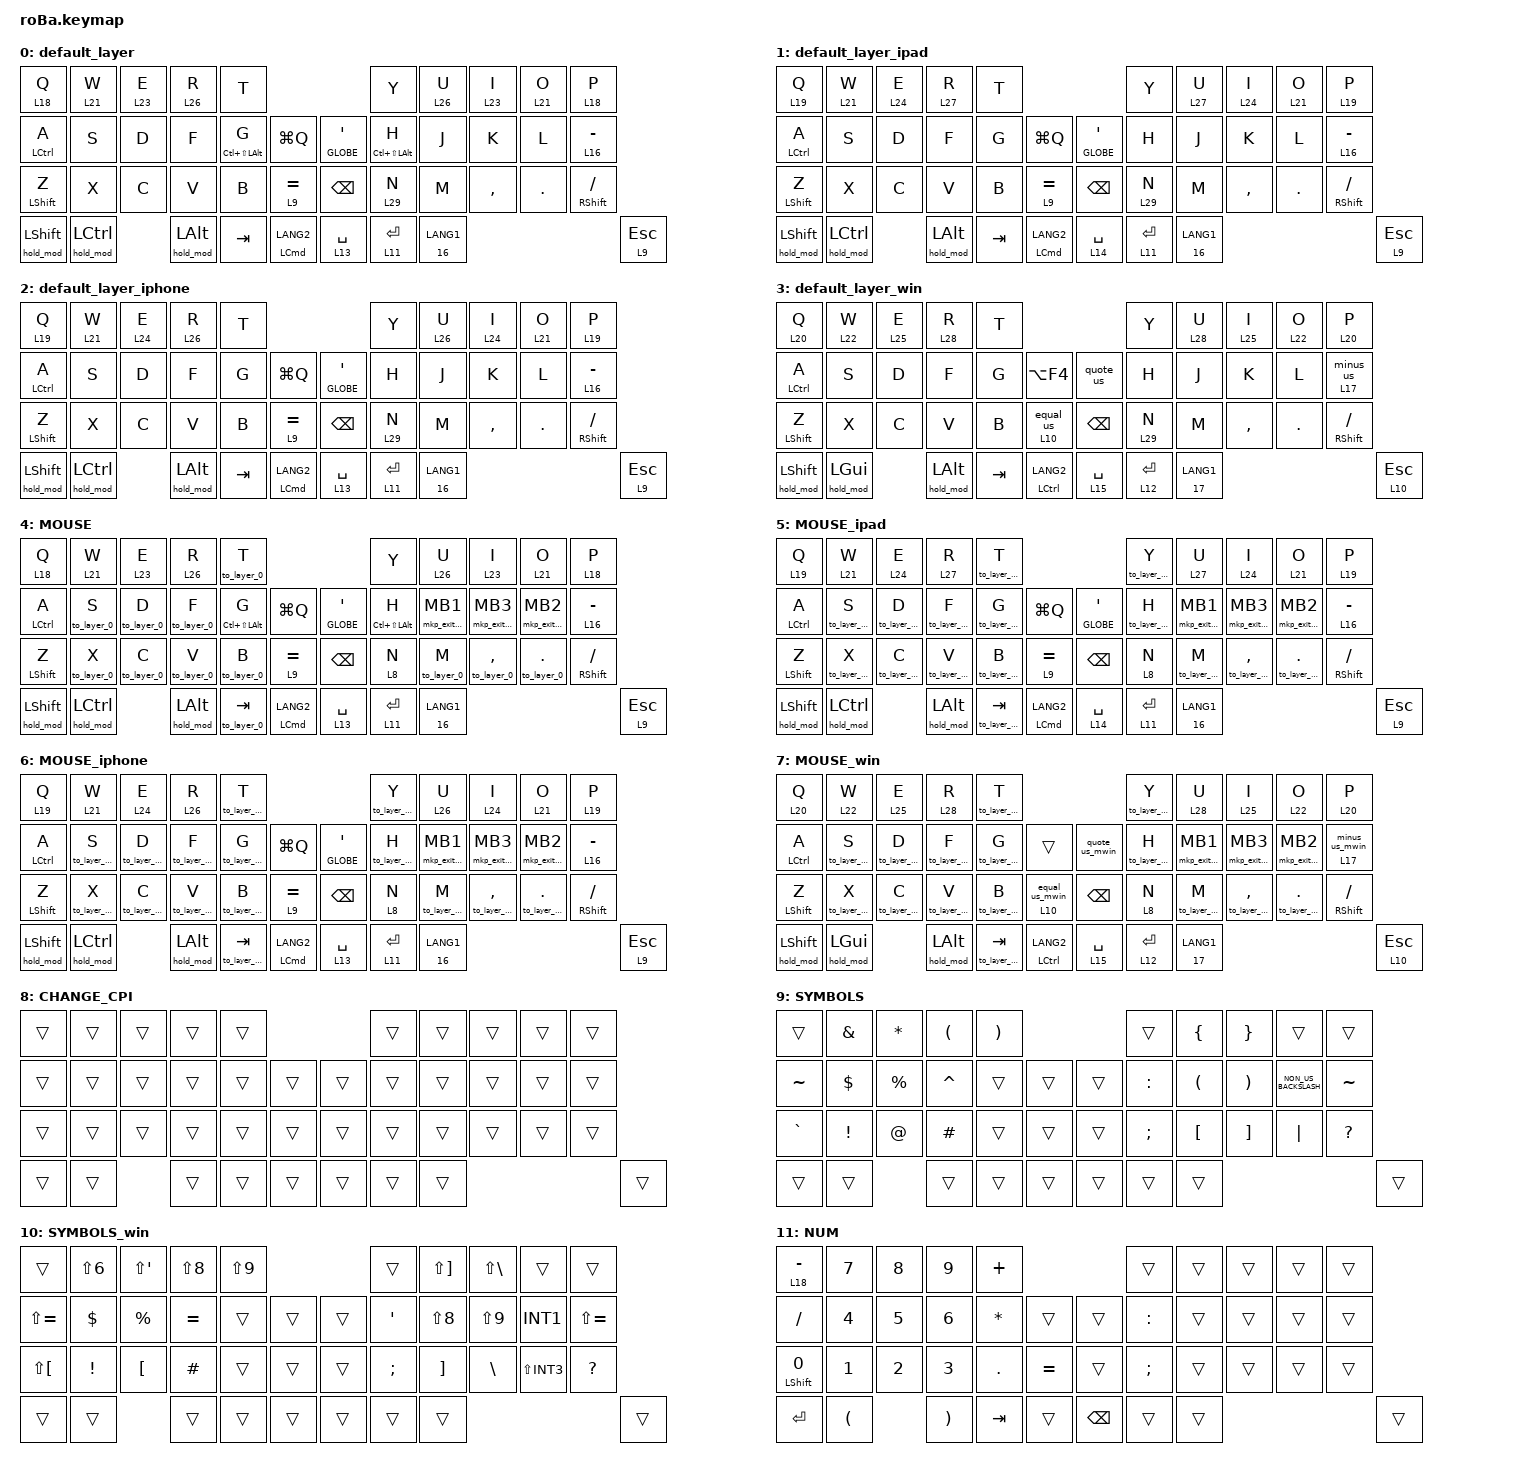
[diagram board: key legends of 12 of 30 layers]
// スクロール量。&msc SCRL_UP/DOWN が SCRL_UP マクロ経由で参照するため、
// pointing.h とエンコーダbehavior(roBa_encoder_behaviors.dtsi)のincludeより
// 必ず前で定義する（後ろに置くと既定値(10)に戻りスクロールが事実上無効になる）。

#define ZMK_POINTING_DEFAULT_SCRL_VAL 80

#include <dt-bindings/zmk/modifiers.h>
#include <behaviors.dtsi>
#include <dt-bindings/zmk/bt.h>
#include <dt-bindings/zmk/keys.h>
#include <dt-bindings/zmk/pointing.h>
#include "roBa_encoder_behaviors.dtsi"

&mt {
    flavor = "balanced";
    quick-tap-ms = <0>;
};

&trackball {
    // 自動マウス層はOS別に出し分けるため、ドライバ側は無効化(-1)。
    // roBa_R.overlay の zip_temp_layer で Mac=層4 / Windows=層7 を切替える。

    automouse-layer = <(-1)>;

    // 18=Mac SCROLL, 20=SCROLL_win（Windows用）。Windowsでもスクロールを有効化。
    // ※editorでレイヤーを増減すると番号がズレるので、SCROLL_winの位置を要確認。

    scroll-layers = <18 19 20>;

    // iPad(層1)等のCPIは overlay の zip_xy_scaler で調整（旧実装は低速CPI=snipe機能だった）。
    // snipe-layers = <1 4>;  // 廃止: iPadをzip_xy_scaler化(overlay)したため。
    // 精密モード(層28)が最上位になるとsnipe判定が外れる問題を回避。CPIは全OS zip_xy_scalerに統一。

    browsing_arrows {
        layers = <21>;
        bindings =
            <&kp LC(TAB)>,
            // 右: 次のタブ,,,,,,,,,,,,,,,,,,,,,,,,,,,,,,,,,,,,,,,,,,,,,,,,,,,,,,,,,,,,,,,,,,,,,,,,,,,,,,,,,,,
            <&kp LC(LS(TAB))>,
            // 左: 前のタブ,,,,,,,,,,,,,,,,,,,,,,,,,,,,,,,,,,,,,,,,,,,,,,,,,,,,,,,,,,,,,,,,,,,,,,,,,,,,,,,,,,,
            <&kp LG(T)>,
            // 上: 新規タブ,,,,,,,,,,,,,,,,,,,,,,,,,,,,,,,,,,,,,,,,,,,,,,,,,,,,,,,,,,,,,,,,,,,,,,,,,,,,,,,,,,,
            <&kp LG(W)>;

        // 下: タブを閉じる

        tick = <150>;
        wait-ms = <5>;
        tap-ms = <5>;
    };

    desktop_arrows {
        layers = <23>;
        bindings =
            <&kp LC(LEFT)>,
            // 右(逆): デスクトップ左,,,,,,,,,,,,,,,,,,,,,,,,,,,,,,,,,,,,,,,,,,,,,,,,,,,,,,,,,,,,,,,,,,,,,,,,,,,,,,,,,,,
            <&kp LC(RIGHT)>,
            // 左(逆): デスクトップ右,,,,,,,,,,,,,,,,,,,,,,,,,,,,,,,,,,,,,,,,,,,,,,,,,,,,,,,,,,,,,,,,,,,,,,,,,,,,,,,,,,,
            <&kp LC(UP)>,
            // 上: Mission Control,,,,,,,,,,,,,,,,,,,,,,,,,,,,,,,,,,,,,,,,,,,,,,,,,,,,,,,,,,,,,,,,,,,,,,,,,,,,,,,,,,,
            <&kp LS(LA(D))>;

        // 下: Shift+Opt+D

        tick = <150>;
        wait-ms = <5>;
        tap-ms = <5>;
    };

    window_arrows {
        layers = <26>;
        bindings =
            <&kp LC(LA(RIGHT))>,
            // 右: 右半分,,,,,,,,,,,,,,,,,,,,,,,,,,,,,,,,,,,,,,,,,,,,,,,,,,,,,,,,,,,,,,,,,,,,,,,,,,,,,,,,,,,
            <&kp LC(LA(LEFT))>,
            // 左: 左半分,,,,,,,,,,,,,,,,,,,,,,,,,,,,,,,,,,,,,,,,,,,,,,,,,,,,,,,,,,,,,,,,,,,,,,,,,,,,,,,,,,,
            <&kp LC(LA(ENTER))>,
            // 上: 最大化,,,,,,,,,,,,,,,,,,,,,,,,,,,,,,,,,,,,,,,,,,,,,,,,,,,,,,,,,,,,,,,,,,,,,,,,,,,,,,,,,,,
            <&kp LS(LG(T))>;

        // 下: Shift+Cmd+T

        tick = <150>;
        wait-ms = <5>;
        tap-ms = <5>;
    };

    // ===== Windows用ジェスチャー（層22/25/28）=====
    // Mac版(21/23/26)と別ブロックにして、Windows相当のショートカットを割当てる。

    browsing_arrows_win {
        layers = <22>;
        bindings =
            <&kp LC(TAB)>,
            // 右: 次のタブ,,,,,,,,,,,,,,,,,,,,,,,,,,,,,,,,,,,,,,,,,,,,,,,,,,,,,,,,,,,,,,,,,,,,,,,,
            <&kp LC(LS(TAB))>,
            // 左: 前のタブ,,,,,,,,,,,,,,,,,,,,,,,,,,,,,,,,,,,,,,,,,,,,,,,,,,,,,,,,,,,,,,,,,,,,,,,,
            <&kp LC(T)>,
            // 上: 新規タブ,,,,,,,,,,,,,,,,,,,,,,,,,,,,,,,,,,,,,,,,,,,,,,,,,,,,,,,,,,,,,,,,,,,,,,,,
            <&kp LC(W)>;

        // 下: タブを閉じる

        tick = <150>;
        wait-ms = <5>;
        tap-ms = <5>;
    };

    desktop_arrows_win {
        layers = <25>;
        bindings =
            <&kp LG(LC(LEFT))>,
            // 右(逆): 仮想デスクトップ左,,,,,,,,,,,,,,,,,,,,,,,,,,,,,,,,,,,,,,,,,,,,,,,,,,,,,,,,,,,,,,,,,,,,,,,,
            <&kp LG(LC(RIGHT))>,
            // 左(逆): 仮想デスクトップ右,,,,,,,,,,,,,,,,,,,,,,,,,,,,,,,,,,,,,,,,,,,,,,,,,,,,,,,,,,,,,,,,,,,,,,,,
            <&kp LG(TAB)>,
            // 上: タスクビュー,,,,,,,,,,,,,,,,,,,,,,,,,,,,,,,,,,,,,,,,,,,,,,,,,,,,,,,,,,,,,,,,,,,,,,,,
            <&dup_tab_win>;

        // 下: タブを複製（Alt+D → Alt+Enter）

        tick = <150>;
        wait-ms = <5>;
        tap-ms = <5>;
    };

    window_arrows_win {
        layers = <28>;
        bindings =
            <&kp LG(RIGHT)>,
            // 右: 右半分スナップ,,,,,,,,,,,,,,,,,,,,,,,,,,,,,,,,,,,,,,,,,,,,,,,,,,,,,,,,,,,,,,,,,,,,,,,,
            <&kp LG(LEFT)>,
            // 左: 左半分スナップ,,,,,,,,,,,,,,,,,,,,,,,,,,,,,,,,,,,,,,,,,,,,,,,,,,,,,,,,,,,,,,,,,,,,,,,,
            <&kp LG(UP)>,
            // 上: 最大化,,,,,,,,,,,,,,,,,,,,,,,,,,,,,,,,,,,,,,,,,,,,,,,,,,,,,,,,,,,,,,,,,,,,,,,,
            <&kp LC(LS(T))>;

        // 下: 閉じたタブ復活

        tick = <150>;
        wait-ms = <5>;
        tap-ms = <5>;
    };

    // ===== iPad用ジェスチャー（層24 = Desktop_Jesture_ipad）=====

    desktop_arrows_ipad {
        layers = <24>;
        bindings =
            <&split_left>,
            // 右: 🌐+←（Split View 左）,,,,,,,,,,,,,,,,,,,,,,,,,,,,,,,,,,,,,,,,,,,,,,,,,,,,,,,,,,,,,,,,
            <&split_right>,
            // 左: 🌐+→（Split View 右）,,,,,,,,,,,,,,,,,,,,,,,,,,,,,,,,,,,,,,,,,,,,,,,,,,,,,,,,,,,,,,,,
            <&app_switcher>,
            // 上: 🌐+↑（Appスイッチャー）,,,,,,,,,,,,,,,,,,,,,,,,,,,,,,,,,,,,,,,,,,,,,,,,,,,,,,,,,,,,,,,,
            <&ipad_home>;

        // 下: 🌐+H（ホーム）

        tick = <150>;
        wait-ms = <5>;
        tap-ms = <5>;
    };

    // ===== iPad用ウィンドウジェスチャー（層27 = Window_Jesture_ipad）=====
    // 設定はMac版(window_arrows)と同一。

    window_arrows_ipad {
        layers = <27>;
        bindings =
            <&ipad_tile_right>,
            // 右: 右にタイル（🌐+Ctrl+→）,,,,,,,,,,,,,,,,,,,
            <&ipad_tile_left>,
            // 左: 左にタイル（🌐+Ctrl+←）,,,,,,,,,,,,,,,,,,,
            <&ipad_fullscreen>,
            // 上: フルスクリーン（🌐+F）,,,,,,,,,,,,,,,,,,,
            <&ipad_show_windows>;

        // 下: 全ウィンドウ表示（🌐+↓）

        tick = <150>;
        wait-ms = <5>;
        tap-ms = <5>;
    };

    // ===== FUNCTION(層16)ジェスチャー: 左右振りでウィンドウを外部ディスプレイへ移動 =====
    // FUNCTIONは右LANGホールド中でCmd(RGUI)が保持されるため、&nomodで保持Cmdを外してから
    // 完全なショートカットを送る。Mac: Rectangle「次/前のディスプレイへ移動」=Ctrl+Opt+Cmd+→/←。

    function_display_move {
        layers = <16>;
        bindings =
            <&nomod LC(LA(LG(RIGHT)))>,
            // 右: 次(右)のディスプレイへ移動,,,,,,,,,,,,,
            <&nomod LC(LA(LG(LEFT)))>,
            // 左: 前(左)のディスプレイへ移動,,,,,,,,,,,,,
            <&nomod LC(LA(ENTER))>,
            // 上: 全画面表示（Magnet 最大化 = Ctrl+Opt+Enter）,,,,,,,,,,,,,
            <&nomod LC(LA(LG(C)))>;

        // 下: 画面中央へ移動（Ctrl+Opt+Cmd+C、サイズは維持）

        tick = <150>;
        wait-ms = <5>;
        tap-ms = <5>;
    };

    // Windows版(層17 FUNCTION_win): 「次/前のモニターへ移動」=Win+Shift+→/←。
    // FUNCTION_winはCtrl(RCTRL)保持なので&nomodで外す。

    function_display_move_win {
        layers = <17>;
        bindings =
            <&nomod LG(LS(RIGHT))>,
            // 右: 次(右)のモニターへ移動,,,,,,,,,,,,,
            <&nomod LG(LS(LEFT))>,
            // 左: 前(左)のモニターへ移動,,,,,,,,,,,,,
            <&nomod LG(UP)>,
            // 上: 全画面表示（Win+↑ 最大化）,,,,,,,,,,,,,
            <&none>;

        // 下: なし

        tick = <150>;
        wait-ms = <5>;
        tap-ms = <5>;
    };
};

/ {
    combos {
        compatible = "zmk,combos";

        num_toggle {
            bindings = <&tog 11>;
            key-positions = <1 0>;
            layers = <0 1 2 4 5 6 11>;
        };

        num_toggle_win {
            bindings = <&tog 12>;
            key-positions = <0 1>;
            layers = <3 7 12>;
        };

        // U+I 同時押しで、現在のOSに応じたスクロール層をトグル。
        // スコープに「デフォルト層＋マウス層＋トグル先(OFF用)」を含める。

        scroll_toggle_mac {
            bindings = <&tog 18>;
            key-positions = <8 9>;
            layers = <0 4 18>;
        };

        scroll_toggle_ipad {
            bindings = <&tog 19>;
            key-positions = <8 9>;
            layers = <1 2 5 6 19>;
        };

        scroll_toggle_win {
            bindings = <&tog 20>;
            key-positions = <8 9>;
            layers = <3 7 20>;
        };

        capslock {
            bindings = <&kp CAPSLOCK>;
            key-positions = <37 38>;
        };

        // Escapeはlayers指定なしだと全OSで発火し、&to_layer_0がBTに触れず
        // レイヤー0(Mac)へ直接切替するため、Windows/iPad/iPhone使用中に発火すると
        // Macレイヤーへ乗っ取られる（Ctrl位置がCmd化しWinキー誤送出・エンコーダ方向反転）。
        // OS別に分離し、最上位アクティブレイヤー基準（combo.cで確認済み）でスコープする。
        // 注意: 精密モード(層8)中はどのOS版も発火しない（scroll_toggle系と同じ制約）。
        // alfred: 実行時にOSデフォルトレイヤー(0-3)を判定するalfred_smart behaviorに統合
        // (2026-07-13)。全デフォルト層/マウス層/精密モード層のどこからでも正しいOSへ発火する。

        alfred {
            bindings = <&alfred_smart>;
            key-positions = <41 39>;
            layers = <0 1 2 3 4 5 6 7 8>;
            require-prior-idle-ms = <200>;
        };

        Escape {
            bindings = <&to_layer_0 ESC>;
            key-positions = <0 39>;
            layers = <0 4>;
            require-prior-idle-ms = <200>;
        };

        Escape_win {
            bindings = <&to_layer_0_win ESC>;
            key-positions = <0 39>;
            layers = <3 7>;
            require-prior-idle-ms = <200>;
        };

        Escape_ipad {
            bindings = <&to_layer_0_ipad ESC>;
            key-positions = <0 39>;
            layers = <1 5>;
            require-prior-idle-ms = <200>;
        };

        Escape_iphone {
            bindings = <&to_layer_0_iphone ESC>;
            key-positions = <0 39>;
            layers = <2 6>;
            require-prior-idle-ms = <200>;
        };

        // BluetoothコンボはNキー(位置29)+Y/U/I/O/Pの組み合わせで、"know"/"funny"/
        // "into"/"menu"/"input"等の日常語で頻出する2文字と一致するため、layers指定
        // なし(常時発火)と合わさってタイピング中に誤爆しやすい。require-prior-idle-ms
        // で「直前の通常キー入力から200ms以内はコンボ扱いしない」を追加し、連続タイピング
        // 中は個々のキーとして送出、意図的に一拍置いて押した時だけコンボとして発火させる。

        Bluetooth_1 {
            bindings = <&bt_mac>;
            key-positions = <5 29>;
            require-prior-idle-ms = <200>;
        };

        Bluetooth_2 {
            bindings = <&bt_ipad>;
            key-positions = <6 29>;
            require-prior-idle-ms = <200>;
        };

        Bluetooth_3 {
            bindings = <&bt_ipad_mini>;
            key-positions = <7 29>;
            require-prior-idle-ms = <200>;
        };

        Bluetooth_4 {
            bindings = <&bt_iphone>;
            key-positions = <8 29>;
            require-prior-idle-ms = <200>;
        };

        Bluetooth_5 {
            bindings = <&bt_win>;
            key-positions = <9 29>;
            require-prior-idle-ms = <200>;
        };

        right_arrow {
            bindings = <&right_arrow>;
            key-positions = <41 20>;
        };

        left_arrow {
            bindings = <&left_arrow>;
            key-positions = <41 18>;
        };

        down_arrow {
            bindings = <&down_arrow>;
            key-positions = <41 19>;
        };

        up_arrow {
            bindings = <&up_arrow>;
            key-positions = <41 7>;
        };

        // m + , (位置30/31) で精密モード(層28 CHANGE_CPI)をトグル。
        // スコープ=各OSのデフォルト層＋マウス層＋28(OFF用)。

        change_cpi_toggle {
            bindings = <&tog 8>;
            key-positions = <30 31>;
            layers = <0 1 2 4 5 6 3 7 8>;
        };

        mouse_left_click {
            bindings = <&mkp MB1>;
            key-positions = <18 19>;
        };

        mouse_right_click {
            bindings = <&mkp MB2>;
            key-positions = <19 20>;
        };

        mouse_middle-click {
            bindings = <&mkp MB3>;
            key-positions = <18 20>;
        };

        // Z + X 同時押しで LSHFT の押しっぱなし状態をトグル。エンコーダのmod-morph
        // （encoder_msc_mac_shift_hscroll等）がShift押下中かを見て上下を反転させる
        // 仕組みを利用し、物理的にShiftを押さえ続けなくても横スクロール相当に切替
        // できる。全レイヤー共通（layers指定なし）。もう一度押すと解除。
    };

    macros {
        left_arrow: left_arrow {
            compatible = "zmk,behavior-macro";
            #binding-cells = <0>;
            wait-ms = <40>;
            tap-ms = <30>;
            bindings = <&kp RGUI &kp Z &kp H>;
            label = "LEFT_ARROW";
        };

        down_arrow: down_arrow {
            compatible = "zmk,behavior-macro";
            #binding-cells = <0>;
            wait-ms = <40>;
            tap-ms = <30>;
            bindings = <&kp RGUI &kp Z &kp J>;
            label = "DOWN_ARROW";
        };

        up_arrow: up_arrow {
            compatible = "zmk,behavior-macro";
            #binding-cells = <0>;
            wait-ms = <40>;
            tap-ms = <30>;
            bindings = <&kp RGUI &kp Z &kp K>;
            label = "UP_ARROW";
        };

        right_arrow: right_arrow {
            compatible = "zmk,behavior-macro";
            #binding-cells = <0>;
            wait-ms = <40>;
            tap-ms = <30>;
            bindings = <&kp RGUI &kp Z &kp L>;
            label = "RIGHT_ARROW";
        };

        to_layer_0: to_layer_0 {
            compatible = "zmk,behavior-macro-one-param";
            #binding-cells = <1>;
            bindings = <&to_base_keep_cpi 0 &macro_param_1to1 &kp MACRO_PLACEHOLDER>;
            label = "TO_LAYER_0";
        };

        to_layer_0_win: to_layer_0_win {
            compatible = "zmk,behavior-macro-one-param";
            #binding-cells = <1>;
            bindings = <&to_base_keep_cpi 3 &macro_param_1to1 &kp MACRO_PLACEHOLDER>;
            label = "TO_LAYER_0_WIN";
        };

        to_layer_0_ipad: to_layer_0_ipad {
            compatible = "zmk,behavior-macro-one-param";
            #binding-cells = <1>;
            bindings = <&to_base_keep_cpi 1 &macro_param_1to1 &kp MACRO_PLACEHOLDER>;
            label = "TO_LAYER_0_IPAD";
        };

        to_layer_0_iphone: to_layer_0_iphone {
            compatible = "zmk,behavior-macro-one-param";
            #binding-cells = <1>;
            bindings = <&to_base_keep_cpi 2 &macro_param_1to1 &kp MACRO_PLACEHOLDER>;
            label = "TO_LAYER_0_IPHONE";
        };

        // Windows: タブを複製。Alt+D でアドレスバーのURLを選択し、
        // Alt+Enter で同じURLを新規タブで開く（＝複製）。

        dup_tab_win: dup_tab_win {
            compatible = "zmk,behavior-macro";
            #binding-cells = <0>;
            wait-ms = <30>;
            tap-ms = <30>;
            bindings = <&kp LA(D) &kp LA(ENTER)>;
            label = "DUP_TAB_WIN";
        };

        // iPad用 Globe(🌐)ショートカット。GLOBE保持→キーをタップ→GLOBE解放。
        // GLOBEはコンシューマ入力切替コードなので &kp GLOBE(x) は不可、マクロ必須。

        control_center: control_center {
            compatible = "zmk,behavior-macro";
            #binding-cells = <0>;
            wait-ms = <10>;
            tap-ms = <10>;
            bindings =
                <&macro_press>,
                <&kp GLOBE>,
                <&macro_tap>,
                <&kp C>,
                <&macro_release>,
                <&kp GLOBE>;

            label = "CONTROL_CENTER";
        };

        app_switcher: app_switcher {
            compatible = "zmk,behavior-macro";
            #binding-cells = <0>;
            wait-ms = <10>;
            tap-ms = <10>;
            bindings =
                <&macro_press>,
                <&kp GLOBE>,
                <&macro_tap>,
                <&kp UP_ARROW>,
                <&macro_release>,
                <&kp GLOBE>;

            label = "APP_SWITCHER";
        };

        notif_center: notif_center {
            compatible = "zmk,behavior-macro";
            #binding-cells = <0>;
            wait-ms = <10>;
            tap-ms = <10>;
            bindings =
                <&macro_press>,
                <&kp GLOBE>,
                <&macro_tap>,
                <&kp N>,
                <&macro_release>,
                <&kp GLOBE>;

            label = "NOTIF_CENTER";
        };

        split_left: split_left {
            compatible = "zmk,behavior-macro";
            #binding-cells = <0>;
            wait-ms = <10>;
            tap-ms = <10>;
            bindings =
                <&macro_press>,
                <&kp GLOBE>,
                <&macro_tap>,
                <&kp LEFT_ARROW>,
                <&macro_release>,
                <&kp GLOBE>;

            label = "SPLIT_LEFT";
        };

        split_right: split_right {
            compatible = "zmk,behavior-macro";
            #binding-cells = <0>;
            wait-ms = <10>;
            tap-ms = <10>;
            bindings =
                <&macro_press>,
                <&kp GLOBE>,
                <&macro_tap>,
                <&kp RIGHT_ARROW>,
                <&macro_release>,
                <&kp GLOBE>;

            label = "SPLIT_RIGHT";
        };

        ipad_home: ipad_home {
            compatible = "zmk,behavior-macro";
            #binding-cells = <0>;
            wait-ms = <10>;
            tap-ms = <10>;
            bindings =
                <&macro_press>,
                <&kp GLOBE>,
                <&macro_tap>,
                <&kp H>,
                <&macro_release>,
                <&kp GLOBE>;

            label = "IPAD_HOME";
        };

        // iPadOS ウィンドウ操作（Globe併用）。Macのウィンドウ分割の代替。

        ipad_tile_left: ipad_tile_left {
            compatible = "zmk,behavior-macro";
            #binding-cells = <0>;
            wait-ms = <10>;
            tap-ms = <10>;
            bindings =
                <&macro_press>,
                <&kp GLOBE>,
                <&macro_tap>,
                <&kp LC(LEFT_ARROW)>,
                <&macro_release>,
                <&kp GLOBE>;

            label = "IPAD_TILE_LEFT";
        };

        ipad_tile_right: ipad_tile_right {
            compatible = "zmk,behavior-macro";
            #binding-cells = <0>;
            wait-ms = <10>;
            tap-ms = <10>;
            bindings =
                <&macro_press>,
                <&kp GLOBE>,
                <&macro_tap>,
                <&kp LC(RIGHT_ARROW)>,
                <&macro_release>,
                <&kp GLOBE>;

            label = "IPAD_TILE_RIGHT";
        };

        ipad_fullscreen: ipad_fullscreen {
            compatible = "zmk,behavior-macro";
            #binding-cells = <0>;
            wait-ms = <10>;
            tap-ms = <10>;
            bindings =
                <&macro_press>,
                <&kp GLOBE>,
                <&macro_tap>,
                <&kp F>,
                <&macro_release>,
                <&kp GLOBE>;

            label = "IPAD_FULLSCREEN";
        };

        ipad_show_windows: ipad_show_windows {
            compatible = "zmk,behavior-macro";
            #binding-cells = <0>;
            wait-ms = <10>;
            tap-ms = <10>;
            bindings =
                <&macro_press>,
                <&kp GLOBE>,
                <&macro_tap>,
                <&kp DOWN_ARROW>,
                <&macro_release>,
                <&kp GLOBE>;

            label = "IPAD_SHOW_WINDOWS";
        };

        // FUNCTION層は右LANGホールドでCmd/Ctrlを保持中。マウスボタンに修飾が
        // 乗ると「戻る/進む」が新タブで開く等の誤動作になるため、保持中modを
        // 一時解除→ボタン送出→復帰する（&mkpを包む）。nomodのマウスボタン版。

        mb_back_mac: mb_back_mac {
            compatible = "zmk,behavior-macro";
            #binding-cells = <0>;
            bindings =
                <&macro_release>,
                <&kp RGUI>,
                <&macro_tap>,
                <&mkp MB4>,
                <&macro_press>,
                <&kp RGUI>;

            label = "MB_BACK_MAC";
        };

        mb_fwd_mac: mb_fwd_mac {
            compatible = "zmk,behavior-macro";
            #binding-cells = <0>;
            bindings =
                <&macro_release>,
                <&kp RGUI>,
                <&macro_tap>,
                <&mkp MB5>,
                <&macro_press>,
                <&kp RGUI>;

            label = "MB_FWD_MAC";
        };

        mb_back_win: mb_back_win {
            compatible = "zmk,behavior-macro";
            #binding-cells = <0>;
            bindings =
                <&macro_release>,
                <&kp RCTRL>,
                <&macro_tap>,
                <&mkp MB4>,
                <&macro_press>,
                <&kp RCTRL>;

            label = "MB_BACK_WIN";
        };

        mb_fwd_win: mb_fwd_win {
            compatible = "zmk,behavior-macro";
            #binding-cells = <0>;
            bindings =
                <&macro_release>,
                <&kp RCTRL>,
                <&macro_tap>,
                <&mkp MB5>,
                <&macro_press>,
                <&kp RCTRL>;

            label = "MB_FWD_WIN";
        };

        // Bluetoothプロファイル切替＋デフォルトレイヤー切替を同時に行う。
        // 2026-07: iPad Pro購入に伴い再編成。
        // prof0=Mac(層0) / prof1=iPad Pro(層1) / prof2=iPad mini(層1) / prof3=iPhone(層2) / prof4=Windows(層3)。
        // iPad Pro/iPad miniは共にiPadOS用の挙動(層1)を共有し、物理的なBluetoothプロファイル番号だけが異なる。

        bt_mac: bt_mac {
            compatible = "zmk,behavior-macro";
            #binding-cells = <0>;
            bindings = <&bt BT_SEL 0 &to 0>;
            label = "BT_MAC";
        };

        bt_ipad: bt_ipad {
            compatible = "zmk,behavior-macro";
            #binding-cells = <0>;
            bindings = <&bt BT_SEL 1 &to 1>;
            label = "BT_IPAD_PRO";
        };

        bt_ipad_mini: bt_ipad_mini {
            compatible = "zmk,behavior-macro";
            #binding-cells = <0>;
            bindings = <&bt BT_SEL 2 &to 1>;
            label = "BT_IPAD_MINI";
        };

        bt_iphone: bt_iphone {
            compatible = "zmk,behavior-macro";
            #binding-cells = <0>;
            bindings = <&bt BT_SEL 3 &to 2>;
            label = "BT_IPHONE";
        };

        bt_win: bt_win {
            compatible = "zmk,behavior-macro";
            #binding-cells = <0>;
            bindings = <&bt BT_SEL 4 &to 3>;
            label = "BT_WIN";
        };

        mkp_exit_AML: mkp_exit_AML {
            compatible = "zmk,behavior-macro-one-param";
            #binding-cells = <1>;
            bindings =
                <&macro_press>,
                <&macro_param_1to1 &mkp MACRO_PLACEHOLDER>,
                <&macro_pause_for_release>,
                <&macro_release>,
                <&macro_param_1to1 &mkp MACRO_PLACEHOLDER>,
                <&macro_tap>,
                <&sl 4>;

            label = "MKP_EXIT_AML";
        };

        mkp_exit_AML_win: mkp_exit_AML_win {
            compatible = "zmk,behavior-macro-one-param";
            #binding-cells = <1>;
            bindings =
                <&macro_press>,
                <&macro_param_1to1 &mkp MACRO_PLACEHOLDER>,
                <&macro_pause_for_release>,
                <&macro_release>,
                <&macro_param_1to1 &mkp MACRO_PLACEHOLDER>,
                <&macro_tap>,
                <&sl 7>;

            label = "MKP_EXIT_AML_WIN";
        };

        mkp_exit_AML_ipad: mkp_exit_AML_ipad {
            compatible = "zmk,behavior-macro-one-param";
            #binding-cells = <1>;
            bindings =
                <&macro_press>,
                <&macro_param_1to1 &mkp MACRO_PLACEHOLDER>,
                <&macro_pause_for_release>,
                <&macro_release>,
                <&macro_param_1to1 &mkp MACRO_PLACEHOLDER>,
                <&macro_tap>,
                <&sl 5>;

            label = "MKP_EXIT_AML_IPAD";
        };

        mkp_exit_AML_iphone: mkp_exit_AML_iphone {
            compatible = "zmk,behavior-macro-one-param";
            #binding-cells = <1>;
            bindings =
                <&macro_press>,
                <&macro_param_1to1 &mkp MACRO_PLACEHOLDER>,
                <&macro_pause_for_release>,
                <&macro_release>,
                <&macro_param_1to1 &mkp MACRO_PLACEHOLDER>,
                <&macro_tap>,
                <&sl 6>;

            label = "MKP_EXIT_AML_IPHONE";
        };
    };

    behaviors {
        cmd_mo: cmd_mo {
            compatible = "zmk,behavior-cmd-mo";
            #binding-cells = <1>;
        };

        nomod: nomod {
            compatible = "zmk,behavior-nomod";
            #binding-cells = <1>;
        };

        ctrl_mo: ctrl_mo {
            compatible = "zmk,behavior-ctrl-mo";
            #binding-cells = <1>;
        };

        to_base_keep_cpi: to_base_keep_cpi {
            compatible = "zmk,behavior-to-base-keep-cpi";
            #binding-cells = <1>;
        };

        toggle_lshift: toggle_lshift {
            compatible = "zmk,behavior-toggle-lshift";
            #binding-cells = <0>;
        };

        rlang: rlang {
            compatible = "zmk,behavior-hold-tap";
            #binding-cells = <2>;
            flavor = "balanced";
            tapping-term-ms = <150>;
            hold-while-undecided;
            bindings = <&cmd_mo>, <&kp>;
        };

        rlang_win: rlang_win {
            compatible = "zmk,behavior-hold-tap";
            #binding-cells = <2>;
            flavor = "balanced";
            tapping-term-ms = <150>;
            hold-while-undecided;
            bindings = <&ctrl_mo>, <&kp>;
        };

        // 左親指Cmd/Ctrl(LANG2)専用: 押下瞬間から修飾キーを有効化(Karabiner to_if_alone相当)
        // &mt本体はホームロー全体に影響するため専用ノードを新設
        // 修飾キー保持専用。&kp と違いHIDへ直接登録し、離すときは参照カウントを
        // 0まで排出する（Cmd固着＝再起動でしか直らない不具合の対策・2026-07-31）。

        hold_mod: hold_mod {
            compatible = "zmk,behavior-hold-mod";
            #binding-cells = <1>;
        };

        mt_fast: mt_fast {
            compatible = "zmk,behavior-hold-tap";
            #binding-cells = <2>;
            flavor = "hold-preferred";
            tapping-term-ms = <150>;
            hold-while-undecided;
            bindings = <&hold_mod>, <&kp>;
        };

        alfred_smart: alfred_smart {
            compatible = "zmk,behavior-alfred-smart";
            #binding-cells = <0>;
        };

        // MOUSE_win(層17)用 US記号補正: タップで層16へexitしつつUS記号を出す

        quote_us_mwin: quote_us_mwin {
            compatible = "zmk,behavior-mod-morph";
            #binding-cells = <0>;
            bindings = <&to_layer_0_win LS(N7)>, <&to_layer_0_win LS(N2)>;

            mods = <(MOD_LSFT|MOD_RSFT)>;
        };

        minus_us_mwin: minus_us_mwin {
            compatible = "zmk,behavior-mod-morph";
            #binding-cells = <0>;
            bindings = <&to_layer_0_win MINUS>, <&to_layer_0_win LS(INT1)>;

            mods = <(MOD_LSFT|MOD_RSFT)>;
        };

        equal_us_mwin: equal_us_mwin {
            compatible = "zmk,behavior-mod-morph";
            #binding-cells = <0>;
            bindings =
                <&to_layer_0_win LS(MINUS)>,
                <&to_layer_0_win LS(SEMICOLON)>;

            mods = <(MOD_LSFT|MOD_RSFT)>;
        };

        lt_minus_us_mwin: lt_minus_us_mwin {
            compatible = "zmk,behavior-hold-tap";
            #binding-cells = <2>;
            flavor = "tap-preferred";
            tapping-term-ms = <200>;
            bindings = <&mo>, <&minus_us_mwin>;
        };

        lt_equal_us_mwin: lt_equal_us_mwin {
            compatible = "zmk,behavior-hold-tap";
            #binding-cells = <2>;
            flavor = "tap-preferred";
            tapping-term-ms = <200>;
            bindings = <&mo>, <&equal_us_mwin>;
        };

        // JIS Windows用US記号補正(default_layer_winのみ)

        quote_us: quote_us {
            compatible = "zmk,behavior-mod-morph";
            #binding-cells = <0>;
            bindings = <&kp LS(N7)>, <&kp LS(N2)>;

            mods = <(MOD_LSFT|MOD_RSFT)>;
        };

        minus_us: minus_us {
            compatible = "zmk,behavior-mod-morph";
            #binding-cells = <0>;
            bindings = <&kp MINUS>, <&kp LS(INT1)>;

            mods = <(MOD_LSFT|MOD_RSFT)>;
        };

        equal_us: equal_us {
            compatible = "zmk,behavior-mod-morph";
            #binding-cells = <0>;
            bindings = <&kp LS(MINUS)>, <&kp LS(SEMICOLON)>;

            mods = <(MOD_LSFT|MOD_RSFT)>;
        };

        lt_minus_us: lt_minus_us {
            compatible = "zmk,behavior-hold-tap";
            #binding-cells = <2>;
            flavor = "tap-preferred";
            tapping-term-ms = <200>;
            bindings = <&mo>, <&minus_us>;
        };

        lt_equal_us: lt_equal_us {
            compatible = "zmk,behavior-hold-tap";
            #binding-cells = <2>;
            flavor = "tap-preferred";
            tapping-term-ms = <200>;
            bindings = <&mo>, <&equal_us>;
        };

        lt_to_layer_0: lt_to_layer_0 {
            compatible = "zmk,behavior-hold-tap";
            label = "LAYER_TAP_TO_0";
            bindings = <&mo>, <&to_layer_0>;

            #binding-cells = <2>;
            tapping-term-ms = <200>;
        };

        lt_to_layer_0_win: lt_to_layer_0_win {
            compatible = "zmk,behavior-hold-tap";
            label = "LAYER_TAP_TO_0_WIN";
            bindings = <&mo>, <&to_layer_0_win>;

            #binding-cells = <2>;
            tapping-term-ms = <200>;
        };

        mt_to_0: mt_to_0 {
            compatible = "zmk,behavior-hold-tap";
            bindings = <&kp>, <&to_layer_0>;

            #binding-cells = <2>;
            flavor = "tap-preferred";
            tapping-term-ms = <200>;
        };

        mt_to_0_win: mt_to_0_win {
            compatible = "zmk,behavior-hold-tap";
            bindings = <&kp>, <&to_layer_0_win>;

            #binding-cells = <2>;
            flavor = "tap-preferred";
            tapping-term-ms = <200>;
        };

        lt_to_layer_0_ipad: lt_to_layer_0_ipad {
            compatible = "zmk,behavior-hold-tap";
            label = "LAYER_TAP_TO_0_IPAD";
            bindings = <&mo>, <&to_layer_0_ipad>;

            #binding-cells = <2>;
            tapping-term-ms = <200>;
        };

        mt_to_0_ipad: mt_to_0_ipad {
            compatible = "zmk,behavior-hold-tap";
            bindings = <&kp>, <&to_layer_0_ipad>;

            #binding-cells = <2>;
            flavor = "tap-preferred";
            tapping-term-ms = <200>;
        };

        lt_to_layer_0_iphone: lt_to_layer_0_iphone {
            compatible = "zmk,behavior-hold-tap";
            label = "LAYER_TAP_TO_0_IPHONE";
            bindings = <&mo>, <&to_layer_0_iphone>;

            #binding-cells = <2>;
            tapping-term-ms = <200>;
        };

        mt_to_0_iphone: mt_to_0_iphone {
            compatible = "zmk,behavior-hold-tap";
            bindings = <&kp>, <&to_layer_0_iphone>;

            #binding-cells = <2>;
            flavor = "tap-preferred";
            tapping-term-ms = <200>;
        };
    };

    keymap {
        compatible = "zmk,keymap";

        default_layer {
            bindings = <
&lt 18 Q            &lt 21 W          &lt 23 E      &lt 26 R  &kp T                                                             &kp Y                   &lt 26 U  &lt 23 I   &lt 21 O  &lt 18 P
&mt LEFT_CONTROL A  &kp S             &kp D         &kp F     &mt LC(LS(LEFT_ALT)) G  &kp LG(Q)         &mt GLOBE SINGLE_QUOTE  &mt LC(LS(LEFT_ALT)) H  &kp J     &kp K      &kp L     &lt 16 MINUS
&mt LEFT_SHIFT Z    &kp X             &kp C         &kp V     &kp B                   &lt 9 EQUAL       &kp BACKSPACE           &lt 29 N                &kp M     &kp COMMA  &kp DOT   &mt RIGHT_SHIFT SLASH
&hold_mod LEFT_SHIFT      &hold_mod LEFT_CONTROL  &hold_mod LEFT_ALT  &kp TAB   &mt_fast LCMD LANG2     &lt 13 SPACE      &lt 11 ENTER            &rlang 16 LANG1                                        &lt 9 ESCAPE
            >;

            sensor-bindings = <&encoder_msc_mac_shift_hscroll>;
        };

        default_layer_ipad {
            bindings = <
&lt 19 Q            &lt 21 W          &lt 24 E      &lt 27 R  &kp T                                                          &kp Y            &lt 27 U  &lt 24 I   &lt 21 O  &lt 19 P
&mt LEFT_CONTROL A  &kp S             &kp D         &kp F     &kp G                &kp LG(Q)         &mt GLOBE SINGLE_QUOTE  &kp H            &kp J     &kp K      &kp L     &lt 16 MINUS
&mt LEFT_SHIFT Z    &kp X             &kp C         &kp V     &kp B                &lt 9 EQUAL       &kp BACKSPACE           &lt 29 N         &kp M     &kp COMMA  &kp DOT   &mt RIGHT_SHIFT SLASH
&hold_mod LEFT_SHIFT      &hold_mod LEFT_CONTROL  &hold_mod LEFT_ALT  &kp TAB   &mt_fast LCMD LANG2  &lt 14 SPACE      &lt 11 ENTER            &rlang 16 LANG1                                 &lt 9 ESCAPE
            >;

            sensor-bindings = <&encoder_msc_mac_shift_hscroll>;
        };

        default_layer_iphone {
            bindings = <
&lt 19 Q            &lt 21 W          &lt 24 E      &lt 26 R  &kp T                                                          &kp Y            &lt 26 U  &lt 24 I   &lt 21 O  &lt 19 P
&mt LEFT_CONTROL A  &kp S             &kp D         &kp F     &kp G                &kp LG(Q)         &mt GLOBE SINGLE_QUOTE  &kp H            &kp J     &kp K      &kp L     &lt 16 MINUS
&mt LEFT_SHIFT Z    &kp X             &kp C         &kp V     &kp B                &lt 9 EQUAL       &kp BACKSPACE           &lt 29 N         &kp M     &kp COMMA  &kp DOT   &mt RIGHT_SHIFT SLASH
&hold_mod LEFT_SHIFT      &hold_mod LEFT_CONTROL  &hold_mod LEFT_ALT  &kp TAB   &mt_fast LCMD LANG2  &lt 13 SPACE      &lt 11 ENTER            &rlang 16 LANG1                                 &lt 9 ESCAPE
            >;

            // Mac/iPadと同じshift判定ロジックを共用。Z+Xで疑似Shift保持中は横スクロール相当に。

            sensor-bindings = <&encoder_msc_mac_shift_hscroll>;
        };

        default_layer_win {
            bindings = <
&lt 20 Q            &lt 22 W      &lt 25 E      &lt 28 R  &kp T                                                       &kp Y                &lt 28 U  &lt 25 I   &lt 22 O  &lt 20 P
&mt LEFT_CONTROL A  &kp S         &kp D         &kp F     &kp G                 &kp LA(F4)             &quote_us      &kp H                &kp J     &kp K      &kp L     &lt_minus_us 17 0
&mt LEFT_SHIFT Z    &kp X         &kp C         &kp V     &kp B                 &lt_equal_us 10 0      &kp BACKSPACE  &lt 29 N             &kp M     &kp COMMA  &kp DOT   &mt RIGHT_SHIFT SLASH
&hold_mod LEFT_SHIFT      &hold_mod LEFT_GUI  &hold_mod LEFT_ALT  &kp TAB   &mt_fast LCTRL LANG2  &lt 15 SPACE           &lt 12 ENTER   &rlang_win 17 LANG1                                 &lt 10 ESCAPE
            >;

            // Windows: エンコーダのスクロール方向も反転（Mac=down_up / Win=up_down）。
            // shift判定ロジックも追加（Z+Xで疑似Shift保持中は横スクロール相当）。
            // ただしWindowsのShift+ホイール=横スクロールは純正機能ではなくアプリ依存。

            sensor-bindings = <&encoder_msc_win_shift_hscroll>;
        };

        MOUSE {
            bindings = <
&lt_to_layer_0 18 Q    &lt_to_layer_0 21 W  &lt_to_layer_0 23 E  &lt_to_layer_0 26 R  &to_layer_0 T                                                                          &kp Y                        &lt_to_layer_0 26 U  &lt_to_layer_0 23 I  &lt_to_layer_0 21 O  &lt_to_layer_0 18 P
&mt_to_0 LCTRL A       &to_layer_0 S        &to_layer_0 D        &to_layer_0 F        &mt_to_0 LC(LS(LEFT_ALT)) G  &kp LG(Q)                    &mt_to_0 GLOBE SINGLE_QUOTE  &mt_to_0 LC(LS(LEFT_ALT)) H  &mkp_exit_AML MB1    &mkp_exit_AML MB3    &mkp_exit_AML MB2    &lt_to_layer_0 16 MINUS
&mt_to_0 LEFT_SHIFT Z  &to_layer_0 X        &to_layer_0 C        &to_layer_0 V        &to_layer_0 B                &lt_to_layer_0 9 EQUAL       &kp BACKSPACE                &lt_to_layer_0 8 N           &to_layer_0 M        &to_layer_0 COMMA    &to_layer_0 DOT      &mt_to_0 RIGHT_SHIFT SLASH
&hold_mod LEFT_SHIFT         &hold_mod LCTRL            &hold_mod LEFT_ALT         &to_layer_0 TAB      &mt_to_0 LCMD LANG2          &lt_to_layer_0 13 SPACE      &lt_to_layer_0 11 ENTER      &rlang 16 LANG1                                                                             &lt_to_layer_0 9 ESC
            >;
        };

        MOUSE_ipad {
            bindings = <
&lt_to_layer_0_ipad 19 Q    &lt_to_layer_0_ipad 21 W  &lt_to_layer_0_ipad 24 E  &lt_to_layer_0_ipad 27 R  &to_layer_0_ipad T                                                                            &to_layer_0_ipad Y       &lt_to_layer_0_ipad 27 U  &lt_to_layer_0_ipad 24 I  &lt_to_layer_0_ipad 21 O  &lt_to_layer_0_ipad 19 P
&mt_to_0_ipad LCTRL A       &to_layer_0_ipad S        &to_layer_0_ipad D        &to_layer_0_ipad F        &to_layer_0_ipad G        &kp LG(Q)                         &mt_to_0_ipad GLOBE SINGLE_QUOTE  &to_layer_0_ipad H       &mkp_exit_AML_ipad MB1    &mkp_exit_AML_ipad MB3    &mkp_exit_AML_ipad MB2    &lt_to_layer_0_ipad 16 MINUS
&mt_to_0_ipad LEFT_SHIFT Z  &to_layer_0_ipad X        &to_layer_0_ipad C        &to_layer_0_ipad V        &to_layer_0_ipad B        &lt_to_layer_0_ipad 9 EQUAL       &kp BACKSPACE                     &lt_to_layer_0_ipad 8 N  &to_layer_0_ipad M        &to_layer_0_ipad COMMA    &to_layer_0_ipad DOT      &mt_to_0_ipad RIGHT_SHIFT SLASH
&hold_mod LEFT_SHIFT              &hold_mod LCTRL                 &hold_mod LEFT_ALT              &to_layer_0_ipad TAB      &mt_to_0_ipad LCMD LANG2  &lt_to_layer_0_ipad 14 SPACE      &lt_to_layer_0_ipad 11 ENTER      &rlang 16 LANG1                                                                                        &lt_to_layer_0_ipad 9 ESC
            >;
        };

        MOUSE_iphone {
            bindings = <
&lt_to_layer_0_iphone 19 Q    &lt_to_layer_0_iphone 21 W  &lt_to_layer_0_iphone 24 E  &lt_to_layer_0_iphone 26 R  &to_layer_0_iphone T                                                                                &to_layer_0_iphone Y       &lt_to_layer_0_iphone 26 U  &lt_to_layer_0_iphone 24 I  &lt_to_layer_0_iphone 21 O  &lt_to_layer_0_iphone 19 P
&mt_to_0_iphone LCTRL A       &to_layer_0_iphone S        &to_layer_0_iphone D        &to_layer_0_iphone F        &to_layer_0_iphone G        &kp LG(Q)                           &mt_to_0_iphone GLOBE SINGLE_QUOTE  &to_layer_0_iphone H       &mkp_exit_AML_iphone MB1    &mkp_exit_AML_iphone MB3    &mkp_exit_AML_iphone MB2    &lt_to_layer_0_iphone 16 MINUS
&mt_to_0_iphone LEFT_SHIFT Z  &to_layer_0_iphone X        &to_layer_0_iphone C        &to_layer_0_iphone V        &to_layer_0_iphone B        &lt_to_layer_0_iphone 9 EQUAL       &kp BACKSPACE                       &lt_to_layer_0_iphone 8 N  &to_layer_0_iphone M        &to_layer_0_iphone COMMA    &to_layer_0_iphone DOT      &mt_to_0_iphone RIGHT_SHIFT SLASH
&hold_mod LEFT_SHIFT                &hold_mod LCTRL                   &hold_mod LEFT_ALT                &to_layer_0_iphone TAB      &mt_to_0_iphone LCMD LANG2  &lt_to_layer_0_iphone 13 SPACE      &lt_to_layer_0_iphone 11 ENTER      &rlang 16 LANG1                                                                                                &lt_to_layer_0_iphone 9 ESC
            >;
        };

        MOUSE_win {
            bindings = <
&lt_to_layer_0_win 20 Q      &lt_to_layer_0_win 22 W  &lt_to_layer_0_win 25 E  &lt_to_layer_0_win 28 R  &to_layer_0_win T                                                                       &to_layer_0_win Y       &lt_to_layer_0_win 28 U  &lt_to_layer_0_win 25 I  &lt_to_layer_0_win 22 O  &lt_to_layer_0_win 20 P
&mt_to_0_win LEFT_CONTROL A  &to_layer_0_win S        &to_layer_0_win D        &to_layer_0_win F        &to_layer_0_win G         &trans                           &quote_us_mwin               &to_layer_0_win H       &mkp_exit_AML_win MB1    &mkp_exit_AML_win MB3    &mkp_exit_AML_win MB2    &lt_minus_us_mwin 17 0
&mt_to_0_win LEFT_SHIFT Z    &to_layer_0_win X        &to_layer_0_win C        &to_layer_0_win V        &to_layer_0_win B         &lt_equal_us_mwin 10 0           &kp BACKSPACE                &lt_to_layer_0_win 8 N  &to_layer_0_win M        &to_layer_0_win COMMA    &to_layer_0_win DOT      &mt_to_0_win RIGHT_SHIFT SLASH
&hold_mod LEFT_SHIFT               &hold_mod LEFT_GUI             &hold_mod LEFT_ALT             &to_layer_0_win TAB      &mt_to_0_win LCTRL LANG2  &lt_to_layer_0_win 15 SPACE      &lt_to_layer_0_win 12 ENTER  &rlang_win 17 LANG1                                                                                &lt_to_layer_0_win 10 ESC
            >;
        };

        CHANGE_CPI {
            bindings = <
&trans  &trans  &trans  &trans  &trans                      &trans  &trans  &trans  &trans  &trans
&trans  &trans  &trans  &trans  &trans  &trans      &trans  &trans  &trans  &trans  &trans  &trans
&trans  &trans  &trans  &trans  &trans  &trans      &trans  &trans  &trans  &trans  &trans  &trans
&trans  &trans  &trans  &trans  &trans  &trans      &trans  &trans                          &trans
            >;
        };

        SYMBOLS {
            bindings = <
&trans     &kp AMPERSAND    &kp ASTERISK  &kp LEFT_PARENTHESIS  &kp RIGHT_PARENTHESIS                      &trans         &kp LEFT_BRACE        &kp RIGHT_BRACE        &trans                &trans
&kp TILDE  &kp DOLLAR       &kp PERCENT   &kp CARET             &trans                 &trans      &trans  &kp COLON      &kp LEFT_PARENTHESIS  &kp RIGHT_PARENTHESIS  &kp NON_US_BACKSLASH  &kp TILDE
&kp GRAVE  &kp EXCLAMATION  &kp AT_SIGN   &kp HASH              &trans                 &trans      &trans  &kp SEMICOLON  &kp LEFT_BRACKET      &kp RIGHT_BRACKET      &kp PIPE              &kp QUESTION
&trans     &trans           &trans        &trans                &trans                 &trans      &trans  &trans                                                                            &trans
            >;

            sensor-bindings = <&encoder_msc_hscroll_mac>;
        };

        SYMBOLS_win {
            bindings = <
&trans         &kp LS(N6)       &kp LS(SQT)  &kp LS(N8)  &kp LS(N9)                      &trans         &kp LS(RBKT)  &kp LS(BSLH)  &trans        &trans
&kp LS(EQUAL)  &kp DOLLAR       &kp PERCENT  &kp EQUAL   &trans      &trans      &trans  &kp SQT        &kp LS(N8)    &kp LS(N9)    &kp INT1      &kp LS(EQUAL)
&kp LS(LBKT)   &kp EXCLAMATION  &kp LBKT     &kp HASH    &trans      &trans      &trans  &kp SEMICOLON  &kp RBKT      &kp BSLH      &kp LS(INT3)  &kp QUESTION
&trans         &trans           &trans       &trans      &trans      &trans      &trans  &trans                                                   &trans
            >;

            sensor-bindings = <&encoder_msc_hscroll_win>;
        };

        NUM {
            bindings = <
&lt 18 MINUS       &kp N7                &kp N8                 &kp N9   &kp PLUS                                 &trans         &trans  &trans  &trans  &trans
&kp SLASH          &kp N4                &kp N5                 &kp N6   &kp ASTERISK  &trans             &trans  &kp COLON      &trans  &trans  &trans  &trans
&mt LEFT_SHIFT N0  &kp N1                &kp N2                 &kp N3   &kp PERIOD    &kp EQUAL          &trans  &kp SEMICOLON  &trans  &trans  &trans  &trans
&kp ENTER          &kp LEFT_PARENTHESIS  &kp RIGHT_PARENTHESIS  &kp TAB  &trans        &kp BACKSPACE      &trans  &trans                                 &trans
            >;
        };

        NUM_win {
            bindings = <
&lt 20 MINUS       &kp N7      &kp N8      &kp N9   &kp LS(SEMI)                              &trans         &trans  &trans  &trans  &trans
&kp SLASH          &kp N4      &kp N5      &kp N6   &kp LS(SQT)   &kp LC(LA(N0))      &trans  &kp SQT        &trans  &trans  &trans  &trans
&mt LEFT_SHIFT N0  &kp N1      &kp N2      &kp N3   &kp PERIOD    &kp LS(MINUS)       &trans  &kp SEMICOLON  &trans  &trans  &trans  &trans
&kp ENTER          &kp LS(N8)  &kp LS(N9)  &kp TAB  &trans        &kp BACKSPACE       &trans  &trans                                 &trans
            >;
        };

        ARROW {
            bindings = <
&kp ESCAPE   &kp LC(LG(LA(LEFT_ARROW)))  &kp UP_ARROW       &kp LA(LG(LC(RIGHT_ARROW)))  &trans                                     &trans  &kp LG(LS(T))    &kp LS(LA(D))  &kp LG(N)    &kp LG(N)
&kp HOME     &kp LEFT_ARROW              &kp DOWN_ARROW     &kp RIGHT_ARROW              &kp END        &kp LG(N0)      &trans      &trans  &kp LS(LC(TAB))  &kp LG(T)      &kp LC(TAB)  &trans
&kp PAGE_UP  &kp LA(LC(LEFT_ARROW))      &kp LA(LC(ENTER))  &kp LA(LC(RIGHT_ARROW))      &kp PAGE_DOWN  &kp LG(N0)      &kp DELETE  &trans  &mkp MB4         &kp LG(W)      &mkp MB5     &trans
&trans       &trans                      &kp LG(LA(LC(C)))  &trans                       &trans         &trans          &trans      &trans                                               &trans
            >;

            sensor-bindings = <&inc_dec_kp LG(MINUS) LG(EQUAL)>;
        };

        ARROW_ipad {
            bindings = <
&kp ESCAPE   &trans           &kp UP_ARROW      &trans            &trans                                     &trans  &kp LG(LS(T))    &trans     &kp LG(N)    &trans
&kp HOME     &kp LEFT_ARROW   &kp DOWN_ARROW    &kp RIGHT_ARROW   &kp END        &kp LG(N0)      &trans      &trans  &kp LS(LC(TAB))  &kp LG(T)  &kp LC(TAB)  &trans
&kp PAGE_UP  &ipad_tile_left  &ipad_fullscreen  &ipad_tile_right  &kp PAGE_DOWN  &kp LG(N0)      &kp DELETE  &trans  &mkp MB4         &kp LG(W)  &mkp MB5     &trans
&trans       &trans           &trans            &trans            &trans         &trans          &trans      &trans                                           &trans
            >;

            sensor-bindings = <&inc_dec_kp LG(MINUS) LG(EQUAL)>;
        };

        ARROW_win {
            bindings = <
&kp ESCAPE   &kp LG(LS(LEFT))  &kp UP_ARROW    &kp LG(LS(RIGHT))  &trans                                     &trans  &kp LC(LS(T))    &dup_tab_win  &kp LC(N)    &trans
&kp HOME     &kp LEFT_ARROW    &kp DOWN_ARROW  &kp RIGHT_ARROW    &kp END        &kp LC(N0)      &trans      &trans  &kp LS(LC(TAB))  &kp LC(T)     &kp LC(TAB)  &trans
&kp PAGE_UP  &kp LG(LEFT)      &kp LG(UP)      &kp LG(RIGHT)      &kp PAGE_DOWN  &kp LC(N0)      &kp DELETE  &trans  &mkp MB4         &kp LC(W)     &mkp MB5     &trans
&trans       &trans            &trans          &trans             &trans         &trans          &trans      &trans                                              &trans
            >;

            sensor-bindings = <&inc_dec_kp LC(MINUS) LC(SEMICOLON)>;
        };

        FUNCTION {
            bindings = <
&trans  &nomod F7  &nomod F8  &nomod F9  &nomod F10                          &nomod F      &nomod RS(COMMA)   &nomod UP_ARROW    &nomod RS(PERIOD)   &nomod LG(N)
&trans  &nomod F4  &nomod F5  &nomod F6  &nomod F11  &trans          &trans  &nomod SPACE  &nomod LEFT_ARROW  &nomod DOWN_ARROW  &nomod RIGHT_ARROW  &trans
&trans  &nomod F1  &nomod F2  &nomod F3  &nomod F12  &nomod F13      &trans  &trans        &mb_back_mac       &nomod LG(W)       &mb_fwd_mac         &trans
&trans  &trans     &trans     &trans     &trans      &trans          &trans  &trans                                                                  &trans
            >;
        };

        FUNCTION_win {
            bindings = <
&trans  &nomod F7  &nomod F8  &nomod F9  &nomod F10                                 &nomod F      &nomod RS(COMMA)   &nomod UP_ARROW    &nomod RS(PERIOD)   &trans
&trans  &nomod F4  &nomod F5  &nomod F6  &nomod F11  &trans          &trans         &nomod SPACE  &nomod LEFT_ARROW  &nomod DOWN_ARROW  &nomod RIGHT_ARROW  &trans
&trans  &nomod F1  &nomod F2  &nomod F3  &nomod F12  &nomod F13      &nomod DELETE  &trans        &mb_back_win       &nomod LC(W)       &mb_fwd_win         &trans
&trans  &trans     &trans     &trans     &trans      &trans          &trans         &trans                                                                  &trans
            >;
        };

        SCROLL {
            bindings = <
&trans  &tog 11       &trans            &trans         &trans                                        &trans  &trans         &kp LG(LA(LC(F)))     &kp LG(LS(NUMBER_4))  &trans
&trans  &kp LC(LEFT)  &kp LC(UP_ARROW)  &kp LC(RIGHT)  &trans  &kp C_BRIGHTNESS_MAXIMUM      &trans  &trans  &kp LS(LC(V))  &kp LG(LS(NUMBER_3))  &kp LG(LS(NUMBER_7))  &trans
&trans  &trans        &trans            &trans         &trans  &kp C_BRI_MAX                 &trans  &trans  &trans         &kp LG(LS(NUMBER_6))  &kp LG(LS(NUMBER_5))  &trans
&trans  &trans        &trans            &trans         &trans  &trans                        &trans  &trans                                                             &trans
            >;

            sensor-bindings = <&inc_dec_kp C_BRI_DN C_BRI_UP>;
        };

        SCROLL_ipad {
            bindings = <
&trans  &notif_center  &ipad_home     &control_center  &trans                             &trans  &trans  &kp LG(LS(NUMBER_4))  &kp LG(LS(NUMBER_3))  &trans
&trans  &split_left    &app_switcher  &split_right     &trans  &kp C_BRI_MAX      &trans  &trans  &trans  &notif_center         &control_center       &trans
&trans  &trans         &trans         &trans           &trans  &kp C_BRI_MAX      &trans  &trans  &trans  &trans                &trans                &trans
&trans  &trans         &trans         &trans           &trans  &trans             &trans  &trans                                                      &trans
            >;

            sensor-bindings = <&inc_dec_kp C_BRI_DN C_BRI_UP>;
        };

        SCROLL_win {
            bindings = <
&trans  &tog 12           &trans       &trans             &trans                             &trans  &trans     &trans               &kp LG(LS(S))  &trans
&trans  &kp LG(LC(LEFT))  &kp LG(TAB)  &kp LG(LC(RIGHT))  &trans  &kp C_BRI_MAX      &trans  &trans  &kp LG(V)  &kp LG(PRINTSCREEN)  &trans         &trans
&trans  &trans            &trans       &trans             &trans  &kp C_BRI_MAX      &trans  &trans  &trans     &trans               &trans         &trans
&trans  &trans            &trans       &trans             &trans  &trans             &trans  &trans                                                 &trans
            >;

            sensor-bindings = <&inc_dec_kp C_BRI_DN C_BRI_UP>;
        };

        Browsing_Jesture {
            bindings = <
&trans  &trans  &trans  &trans  &trans                          &kp LG(LS(T))  &kp LS(LA(D))    &kp LG(T)    &trans  &trans
&trans  &trans  &trans  &trans  &trans  &kp LG(N0)      &trans  &kp LG(R)      &kp LS(LC(TAB))  &kp LC(TAB)  &trans  &trans
&trans  &trans  &trans  &trans  &trans  &kp LG(N0)      &trans  &trans         &kp LG(W)        &trans       &trans  &trans
&trans  &trans  &trans  &trans  &trans  &trans          &trans  &trans                                               &trans
            >;

            sensor-bindings = <&inc_dec_kp LG(MINUS) LG(EQUAL)>;
        };

        Browsing_Jesture_win {
            bindings = <
&trans  &trans  &trans  &trans  &trans                          &kp LC(LS(T))  &dup_tab_win     &kp LC(T)    &trans  &trans
&trans  &trans  &trans  &trans  &trans  &kp LC(N0)      &trans  &kp LC(R)      &kp LC(LS(TAB))  &kp LC(TAB)  &trans  &trans
&trans  &trans  &trans  &trans  &trans  &kp LC(N0)      &trans  &trans         &kp LC(W)        &trans       &trans  &trans
&trans  &trans  &trans  &trans  &trans  &trans          &trans  &trans                                               &trans
            >;

            sensor-bindings = <&inc_dec_kp LC(MINUS) LC(SEMICOLON)>;
        };

        Desktop_Jesture {
            bindings = <
&trans  &trans        &trans            &kp LC(UP_ARROW)  &trans                          &trans  &kp LC(UP_ARROW)  &trans            &trans         &trans
&trans  &kp LC(LEFT)  &kp LC(UP_ARROW)  &kp LC(RIGHT)     &trans  &kp K_MUTE      &trans  &trans  &kp LC(LEFT)      &kp LC(UP_ARROW)  &kp LC(RIGHT)  &trans
&trans  &trans        &trans            &trans            &trans  &kp K_MUTE      &trans  &trans  &trans            &trans            &trans         &trans
&trans  &trans        &trans            &trans            &trans  &trans          &trans  &trans                                                     &trans
            >;

            sensor-bindings = <&inc_dec_kp C_VOL_DN C_VOL_UP>;
        };

        Desktop_Jesture_ipad {
            bindings = <
&trans  &notif_center  &ipad_home     &control_center  &trans                          &trans  &notif_center  &ipad_home     &control_center  &trans
&trans  &split_left    &app_switcher  &split_right     &trans  &kp K_MUTE      &trans  &trans  &split_left    &app_switcher  &split_right     &trans
&trans  &trans         &trans         &trans           &trans  &kp K_MUTE      &trans  &trans  &trans         &trans         &trans           &trans
&trans  &trans         &trans         &trans           &trans  &trans          &trans  &trans                                                 &trans
            >;

            sensor-bindings = <&inc_dec_kp C_VOL_DN C_VOL_UP>;
        };

        Desktop_Jesture_win {
            bindings = <
&trans  &trans            &trans       &trans             &trans                          &trans  &trans        &trans       &trans         &trans
&trans  &kp LG(LC(LEFT))  &kp LG(TAB)  &kp LG(LC(RIGHT))  &trans  &kp K_MUTE      &trans  &trans  &kp LG(LEFT)  &kp LG(TAB)  &kp LG(RIGHT)  &trans
&trans  &trans            &trans       &trans             &trans  &kp K_MUTE      &trans  &trans  &trans        &trans       &trans         &trans
&trans  &trans            &trans       &trans             &trans  &trans          &trans  &trans                                            &trans
            >;

            sensor-bindings = <&inc_dec_kp C_VOL_DN C_VOL_UP>;
        };

        Window_Jesture {
            bindings = <
&trans  &trans  &trans  &trans  &trans                      &kp LA(LC(ENTER))  &trans  &trans             &trans  &trans
&trans  &trans  &trans  &trans  &trans  &trans      &trans  &kp LC(LA(LEFT))   &trans  &kp LA(LC(RIGHT))  &trans  &trans
&trans  &trans  &trans  &trans  &trans  &trans      &trans  &kp LG(LA(LC(C)))  &trans  &trans             &trans  &trans
&trans  &trans  &trans  &trans  &trans  &trans      &trans  &trans                                                &trans
            >;

            sensor-bindings = <&encoder_msc_hscroll_mac>;
        };

        Window_Jesture_ipad {
            bindings = <
&trans  &trans  &trans  &trans  &trans                      &ipad_fullscreen  &trans  &trans            &trans  &trans
&trans  &trans  &trans  &trans  &trans  &trans      &trans  &ipad_tile_left   &trans  &ipad_tile_right  &trans  &trans
&trans  &trans  &trans  &trans  &trans  &trans      &trans  &trans            &trans  &trans            &trans  &trans
&trans  &trans  &trans  &trans  &trans  &trans      &trans  &trans                                              &trans
            >;

            sensor-bindings = <&encoder_msc_hscroll_mac>;
        };

        Window_Jesture_win {
            bindings = <
&trans  &trans  &trans  &trans  &trans                      &kp LG(UP_ARROW)  &trans  &trans         &trans  &trans
&trans  &trans  &trans  &trans  &trans  &trans      &trans  &kp LG(LEFT)      &trans  &kp LG(RIGHT)  &trans  &trans
&trans  &trans  &trans  &trans  &trans  &trans      &trans  &trans            &trans  &trans         &trans  &trans
&trans  &trans  &trans  &trans  &trans  &trans      &trans  &trans                                           &trans
            >;

            sensor-bindings = <&encoder_msc_hscroll_win>;
        };

        BLUETOOTH {
            bindings = <
&to 0   &to 1   &to 1   &to 2   &to 3                       &bt_mac  &bt_ipad  &bt_ipad_mini  &bt_iphone  &bt_win
&trans  &trans  &trans  &trans  &trans  &trans      &trans  &trans   &trans    &trans         &trans      &trans
&trans  &trans  &trans  &trans  &trans  &trans      &trans  &trans   &trans    &trans         &trans      &bt BT_CLR
&trans  &trans  &trans  &trans  &trans  &trans      &trans  &trans                                        &bt BT_CLR_ALL
            >;
        };

        // レイヤー31: 横画面モード。有効な間トラックボールのX/Yを入れ替える
        // （入れ替えは roBa_R.overlay の trackball_listener 側で設定）。
        // 全キー透過なので、このモード中も通常の打鍵はそのまま使える。
    };
};
